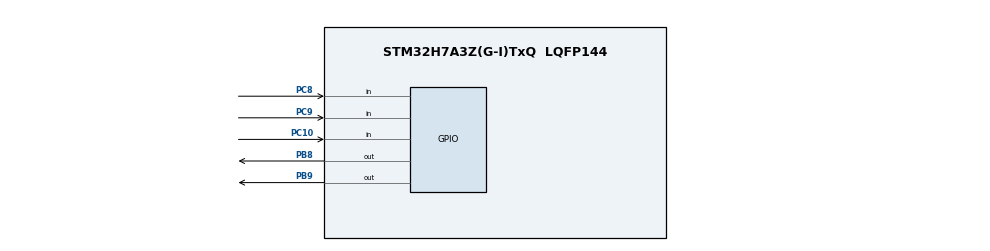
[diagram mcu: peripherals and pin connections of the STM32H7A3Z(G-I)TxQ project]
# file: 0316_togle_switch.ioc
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Mcu.Family=STM32H7
Mcu.Name=STM32H7A3Z(G-I)TxQ
Mcu.Package=LQFP144
NVIC.PriorityGroup=NVIC_PRIORITYGROUP_4
PB8.Signal=GPIO_Output
PB9.Signal=GPIO_Output
PC10.Signal=GPIO_Input
PC8.Signal=GPIO_Input
PC9.Signal=GPIO_Input
ProjectManager.HeapSize=0x200
ProjectManager.StackSize=0x400
ProjectManager.TargetToolchain=STM32CubeIDE
RCC.ADCFreq_Value=129000000
RCC.APB1Freq_Value=64000000
RCC.APB2Freq_Value=64000000
RCC.APB3Freq_Value=64000000
RCC.APB4Freq_Value=64000000
RCC.CortexFreq_Value=64000000
RCC.HCLKFreq_Value=64000000
RCC.SYSCLKFreq_VALUE=64000000
RCC.USBFreq_Value=129000000
board=custom

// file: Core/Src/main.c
/* USER CODE BEGIN Header */
/**
  ******************************************************************************
  * @file           : main.c
  * @brief          : Main program body
  ******************************************************************************
  * @attention
  *
  * Copyright (c) 2023 STMicroelectronics.
  * All rights reserved.
  *
  * This software is licensed under terms that can be found in the LICENSE file
  * in the root directory of this software component.
  * If no LICENSE file comes with this software, it is provided AS-IS.
  *
  ******************************************************************************
  */
/* USER CODE END Header */
#include "main.h"

void SystemClock_Config(void);
static void MX_GPIO_Init(void);

int main(void)
{

  /* MCU Configuration--------------------------------------------------------*/

  /* Reset of all peripherals, Initializes the Flash interface and the Systick. */
  HAL_Init();

  /* Configure the system clock */
  SystemClock_Config();

  /* Initialize all configured peripherals */
  MX_GPIO_Init();

  /* Infinite loop */
  /* USER CODE BEGIN WHILE */
  while (1)
  {
	  if(HAL_GPIO_ReadPin(GPIOC, GPIO_PIN_9)==1)
	  {
		  if(HAL_GPIO_ReadPin(GPIOC, GPIO_PIN_10)==1)
		  {
		  HAL_GPIO_WritePin(GPIOB, GPIO_PIN_9, SET);
		  HAL_Delay(100);
		  HAL_GPIO_WritePin(GPIOB, GPIO_PIN_9, RESET);
		  HAL_Delay(100);
		  }
		  else if(HAL_GPIO_ReadPin(GPIOC, GPIO_PIN_8)==1)
		  {
		  HAL_GPIO_WritePin(GPIOB, GPIO_PIN_8, RESET);
		  HAL_Delay(100);
		  HAL_GPIO_WritePin(GPIOB, GPIO_PIN_8, SET);
		  HAL_Delay(100);
		  }
	  }
    /* USER CODE END WHILE */

  }
}

void SystemClock_Config(void)
{
  RCC_OscInitTypeDef RCC_OscInitStruct = {0};
  RCC_ClkInitTypeDef RCC_ClkInitStruct = {0};

  /** Supply configuration update enable
  */
  HAL_PWREx_ConfigSupply(PWR_DIRECT_SMPS_SUPPLY);
  /** Configure the main internal regulator output voltage
  */
  __HAL_PWR_VOLTAGESCALING_CONFIG(PWR_REGULATOR_VOLTAGE_SCALE3);

  while(!__HAL_PWR_GET_FLAG(PWR_FLAG_VOSRDY)) {}
  /** Initializes the RCC Oscillators according to the specified parameters
  * in the RCC_OscInitTypeDef structure.
  */
  RCC_OscInitStruct.OscillatorType = RCC_OSCILLATORTYPE_HSI;
  RCC_OscInitStruct.HSIState = RCC_HSI_DIV1;
  RCC_OscInitStruct.HSICalibrationValue = RCC_HSICALIBRATION_DEFAULT;
  RCC_OscInitStruct.PLL.PLLState = RCC_PLL_NONE;
  if (HAL_RCC_OscConfig(&RCC_OscInitStruct) != HAL_OK)
  {
    Error_Handler();
  }
  /** Initializes the CPU, AHB and APB buses clocks
  */
  RCC_ClkInitStruct.ClockType = RCC_CLOCKTYPE_HCLK|RCC_CLOCKTYPE_SYSCLK
                              |RCC_CLOCKTYPE_PCLK1|RCC_CLOCKTYPE_PCLK2
                              |RCC_CLOCKTYPE_D3PCLK1|RCC_CLOCKTYPE_D1PCLK1;
  RCC_ClkInitStruct.SYSCLKSource = RCC_SYSCLKSOURCE_HSI;
  RCC_ClkInitStruct.SYSCLKDivider = RCC_SYSCLK_DIV1;
  RCC_ClkInitStruct.AHBCLKDivider = RCC_HCLK_DIV1;
  RCC_ClkInitStruct.APB3CLKDivider = RCC_APB3_DIV1;
  RCC_ClkInitStruct.APB1CLKDivider = RCC_APB1_DIV1;
  RCC_ClkInitStruct.APB2CLKDivider = RCC_APB2_DIV1;
  RCC_ClkInitStruct.APB4CLKDivider = RCC_APB4_DIV1;

  if (HAL_RCC_ClockConfig(&RCC_ClkInitStruct, FLASH_LATENCY_2) != HAL_OK)
  {
    Error_Handler();
  }
}

static void MX_GPIO_Init(void)
{
  GPIO_InitTypeDef GPIO_InitStruct = {0};

  /* GPIO Ports Clock Enable */
  __HAL_RCC_GPIOC_CLK_ENABLE();
  __HAL_RCC_GPIOB_CLK_ENABLE();

  /*Configure GPIO pin Output Level */
  HAL_GPIO_WritePin(GPIOB, GPIO_PIN_8|GPIO_PIN_9, GPIO_PIN_RESET);

  /*Configure GPIO pins : PC8 PC9 PC10 */
  GPIO_InitStruct.Pin = GPIO_PIN_8|GPIO_PIN_9|GPIO_PIN_10;
  GPIO_InitStruct.Mode = GPIO_MODE_INPUT;
  GPIO_InitStruct.Pull = GPIO_NOPULL;
  HAL_GPIO_Init(GPIOC, &GPIO_InitStruct);

  /*Configure GPIO pins : PB8 PB9 */
  GPIO_InitStruct.Pin = GPIO_PIN_8|GPIO_PIN_9;
  GPIO_InitStruct.Mode = GPIO_MODE_OUTPUT_PP;
  GPIO_InitStruct.Pull = GPIO_NOPULL;
  GPIO_InitStruct.Speed = GPIO_SPEED_FREQ_LOW;
  HAL_GPIO_Init(GPIOB, &GPIO_InitStruct);

}

void Error_Handler(void)
{
  __disable_irq();
  while (1)
  {
  }
}
